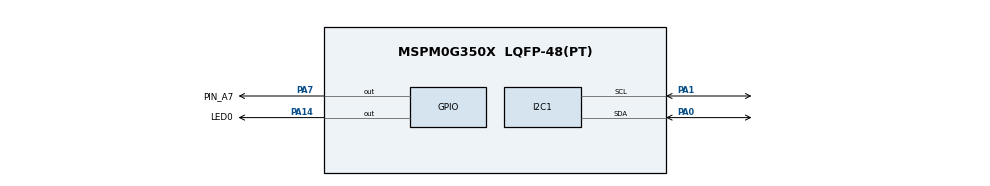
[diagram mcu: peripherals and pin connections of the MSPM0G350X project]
/**
 * @cliArgs --device "MSPM0G350X" --part "Default" --package "LQFP-48(PT)" --product "mspm0_sdk@2.10.00.04"
 * @versions {"tool":"1.26.2+4477"}
 */

/**
 * Import the modules used in this configuration.
 */
const GPIO    = scripting.addModule("/ti/driverlib/GPIO", {}, false);
const GPIO1   = GPIO.addInstance();
const GPIO2   = GPIO.addInstance();
const I2C     = scripting.addModule("/ti/driverlib/I2C", {}, false);
const I2C1    = I2C.addInstance();
const SYSCTL  = scripting.addModule("/ti/driverlib/SYSCTL");
const SYSTICK = scripting.addModule("/ti/driverlib/SYSTICK");

/**
 * Write custom configuration values to the imported modules.
 */
GPIO1.$name                         = "LED";
GPIO1.associatedPins.create(1);
GPIO1.associatedPins[0].$name       = "LED0";
GPIO1.associatedPins[0].pin.$assign = "PA14";

GPIO2.$name                         = "MPU6050_INT";
GPIO2.associatedPins.create(1);
GPIO2.associatedPins[0].$name       = "PIN_A7";
GPIO2.associatedPins[0].pin.$assign = "PA7";

I2C1.$name                             = "MPU6050";
I2C1.basicEnableController             = true;
I2C1.advDigitalGlitchFilter            = "CLOCKS_1";
I2C1.advControllerRXFIFOTRIG           = "BYTES_8";
I2C1.advControllerTXFIFOTRIG           = "BYTES_7";
I2C1.enableDMAEvent1                   = false;
I2C1.enableDMAEvent2                   = false;
I2C1.peripheral.$assign                = "I2C0";
I2C1.peripheral.sdaPin.$assign         = "PA0";
I2C1.peripheral.sclPin.$assign         = "PA1";
I2C1.sdaPinConfig.$name                = "ti_driverlib_gpio_GPIOPinGeneric0";
I2C1.sdaPinConfig.hideOutputInversion  = scripting.forceWrite(false);
I2C1.sdaPinConfig.onlyInternalResistor = scripting.forceWrite(false);
I2C1.sdaPinConfig.passedPeripheralType = scripting.forceWrite("Digital");
I2C1.sclPinConfig.$name                = "ti_driverlib_gpio_GPIOPinGeneric1";
I2C1.sclPinConfig.hideOutputInversion  = scripting.forceWrite(false);
I2C1.sclPinConfig.onlyInternalResistor = scripting.forceWrite(false);
I2C1.sclPinConfig.passedPeripheralType = scripting.forceWrite("Digital");

const Board = scripting.addModule("/ti/driverlib/Board", {}, false);

SYSCTL.forceDefaultClkConfig = true;

SYSTICK.periodEnable    = true;
SYSTICK.period          = 32000;
SYSTICK.interruptEnable = true;
SYSTICK.systickEnable   = true;

const ProjectConfig              = scripting.addModule("/ti/project_config/ProjectConfig", {}, false);
ProjectConfig.migrationCondition = true;
